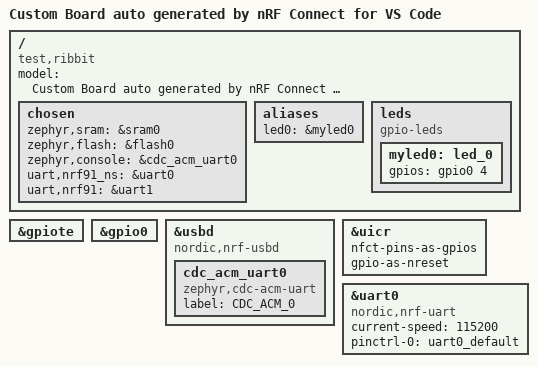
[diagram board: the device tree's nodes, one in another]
/dts-v1/;
#include <nordic/nrf52833_qdaa.dtsi>
#include "ribbit_solar_nrf52-pinctrl.dtsi"

/ {
	model = "Custom Board auto generated by nRF Connect for VS Code";
	compatible = "test,ribbit";

	chosen {
		zephyr,sram = &sram0;
		zephyr,flash = &flash0;
		zephyr,console = &cdc_acm_uart0;
		// zephyr,nrf91_ns_console = &cdc_acm_uart1;
		uart,nrf91_ns = &uart0;
		// zephyr,nrf91_console = &cdc_acm_uart2;
		uart,nrf91 = &uart1;
	};

	aliases {
		led0 = &myled0;
	};

	leds {
		compatible = "gpio-leds";
		// not actually an LED, but a GPIO that is easily accessible for probing
		myled0: led_0 {
				gpios = <&gpio0 4 GPIO_ACTIVE_HIGH>;
		};
	};
};

&gpiote {
	status = "okay";
};

&gpio0 {
	status = "okay";
};

zephyr_udc0: &usbd {
	compatible = "nordic,nrf-usbd";
	status = "okay";
};

&zephyr_udc0 {
	// nRF52
	cdc_acm_uart0: cdc_acm_uart0 {
		compatible = "zephyr,cdc-acm-uart";
		label = "CDC_ACM_0";
	};

	// // nRF91 ns
	// cdc_acm_uart1: cdc_acm_uart1 {
	// 	compatible = "zephyr,cdc-acm-uart";
	// 	label = "CDC_ACM_1";
	// };

	// // nRF91
	// cdc_acm_uart2: cdc_acm_uart2 {
	// 	compatible = "zephyr,cdc-acm-uart";
	// 	label = "CDC_ACM_2";
	// };
};

&uicr {
    nfct-pins-as-gpios; // Necessary to use uart0 pins
	gpio-as-nreset;
};

&uart0 {
	compatible = "nordic,nrf-uart";
	status = "okay";
	current-speed = <115200>;
	pinctrl-0 = <&uart0_default>;
	// pinctrl-1 = <&uart0_sleep>;
	pinctrl-names = "default"; // , "sleep";
};

// &uart1 {
// 	compatible = "nordic,nrf-uarte";
// 	status = "okay";
// 	current-speed = <115200>;
// 	pinctrl-0 = <&uart1_default>;
// 	pinctrl-1 = <&uart1_sleep>;
// 	pinctrl-names = "default", "sleep";
// };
